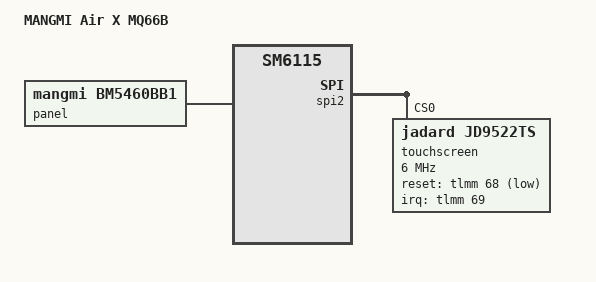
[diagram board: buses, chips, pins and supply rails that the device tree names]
// SPDX-License-Identifier: BSD-3-Clause
/*
 * Copyright (c) 2025, ROCKNIX
 */

/dts-v1/;

#include "sm6115-mangmi-air-x-base.dtsi"

/ {
	model = "MANGMI Air X MQ66B";
	compatible = "mangmi,sm6115-air-x-mq66b", "qcom,sm6115";
};

&panel {
	compatible = "mangmi,bm5460bb1";
};

&spi2 {
	status = "okay";

	touchscreen@0 {
		compatible = "jadard,jd9522ts";
		reg = <0>;
		spi-max-frequency = <6000000>;

		interrupt-parent = <&tlmm>;
		interrupts = <69 IRQ_TYPE_EDGE_FALLING>;
		reset-gpios = <&tlmm 68 GPIO_ACTIVE_LOW>;

		touchscreen-size-x = <1080>;
		touchscreen-size-y = <1920>;
		jadard,panel-max-points = <5>;

		pinctrl-names = "default";
		pinctrl-0 = <&ts_irq_default>;
	};
};
